# qdec_reva register map
Registers are read-write, no defined reset value unless marked. A register's access mark holds for its fields unless they carry their own. Offsets are from the block's base; lines under a group give offsets from that group; [hi:lo] are bit positions; {n}, {i} and the like mark numbered series; 'fields as' and 'values as' point back to an identical list; <NAME> marks a mode.

## Memory map
0x40063000 QDEC size 0x1000 — Quadrature Encoder Interface

## QDEC — Quadrature Encoder Interface
Base 0x40063000
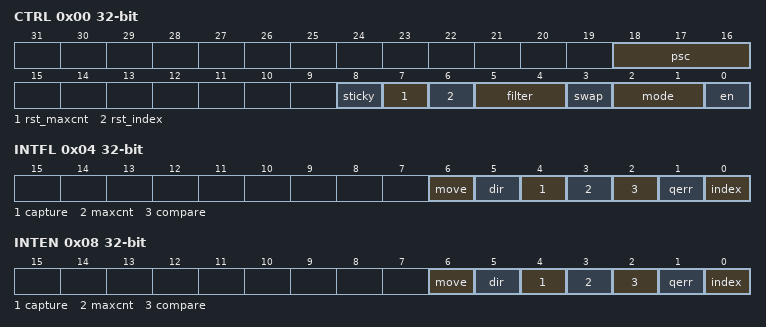
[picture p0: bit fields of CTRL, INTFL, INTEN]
0x00 CTRL — Control Register.
  [18:16] psc
    0=div1; 1=div2; 2=div4; 3=div8; 4=div16; 5=div32; 6=div64; 7=div128
  [8] sticky
  [7] rst_maxcnt
  [6] rst_index
  [5:4] filter
    0=1_sample; 1=2_samples; 2=3_samples; 3=4_samples
  [3] swap
  [2:1] mode
    0=x1mode; 1=x2mode; 2=x4mode
  [0] en
    0=disable; 1=enable
0x04 INTFL — Interrupt Flag Register.
  [6] move write-1-clears, [5] dir write-1-clears, [4] capture write-1-clears, [3] maxcnt write-1-clears, [2] compare write-1-clears, [1] qerr write-1-clears, [0] index write-1-clears
0x08 INTEN — Interrupt Enable Register.
  [6] move, [5] dir, [4] capture, [3] maxcnt, [2] compare, [1] qerr, [0] index
0x0C MAXCNT — Maximum Count Register.
  [31:0] maxcnt
0x10 INITIAL — Initial Count Register.
  [31:0] initial
0x14 COMPARE
  [31:0] compare
0x18 INDEX ro — Index Register. count captured when QEI fired
  [31:0] index
0x1C CAPTURE ro — Capture Register. counter captured when QES fired
  [31:0] capture
0x20 STATUS ro
  [0] dir
0x24 POSITION ro — Count Register. raw counter value
  [31:0] position
0x28 CAPDLY — delay CAPTURE
  [31:0] capdly
